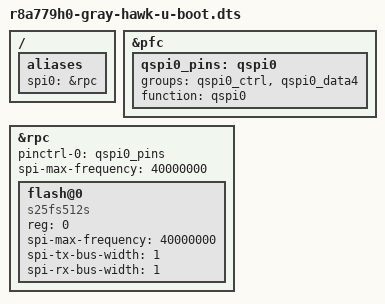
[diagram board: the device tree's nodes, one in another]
// SPDX-License-Identifier: GPL-2.0
/*
 * Device Tree Source extras for U-Boot for the Gray Hawk board
 *
 * Copyright (C) 2023 Renesas Electronics Corp.
 */

#include "r8a779h0-gray-hawk.dts"
#include "r8a779h0-u-boot.dtsi"

/ {
	aliases {
		spi0 = &rpc;
	};
};

&pfc {
	qspi0_pins: qspi0 {
		groups = "qspi0_ctrl", "qspi0_data4";
		function = "qspi0";
	};
};

&rpc {
	pinctrl-0 = <&qspi0_pins>;
	pinctrl-names = "default";

	#address-cells = <1>;
	#size-cells = <0>;
	spi-max-frequency = <40000000>;
	status = "okay";

	flash@0 {
		#address-cells = <1>;
		#size-cells = <1>;
		compatible = "s25fs512s", "jedec,spi-nor";
		reg = <0>;
		spi-max-frequency = <40000000>;
		spi-tx-bus-width = <1>;
		spi-rx-bus-width = <1>;
	};
};
